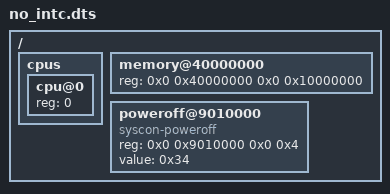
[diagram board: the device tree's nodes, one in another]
/dts-v1/;

/ {
	#address-cells = <2>;
	#size-cells = <2>;

	cpus {
		#address-cells = <1>;
		#size-cells = <0>;
		cpu@0 {
			device_type = "cpu";
			reg = <0>;
		};
	};

	memory@40000000 {
		device_type = "memory";
		reg = <0x0 0x40000000 0x0 0x10000000>;
	};

	poweroff@9010000 {
		compatible = "syscon-poweroff";
		reg = <0x0 0x9010000 0x0 0x4>;
		value = <0x34>;
	};
};
